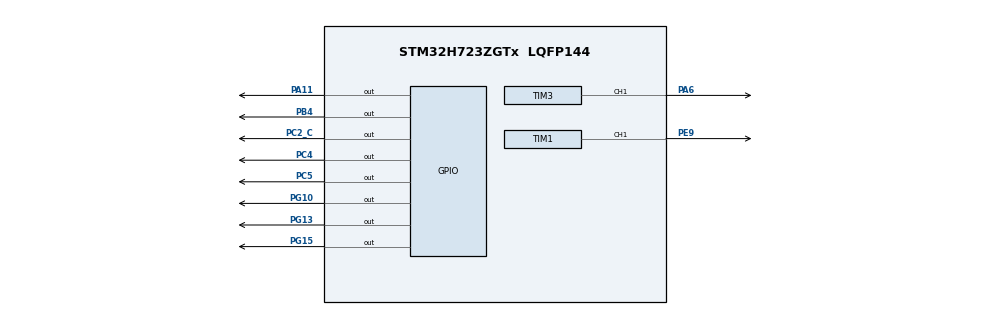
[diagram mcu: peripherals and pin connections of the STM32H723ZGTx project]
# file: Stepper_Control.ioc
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Mcu.Family=STM32H7
Mcu.Name=STM32H723ZGTx
Mcu.Package=LQFP144
NVIC.PriorityGroup=NVIC_PRIORITYGROUP_4
NVIC.TIM1_BRK_IRQn=true\:1\:0\:true\:false\:true\:true\:true\:true
NVIC.TIM23_IRQn=true\:0\:0\:false\:false\:true\:true\:true\:true
NVIC.TIM3_IRQn=true\:1\:0\:true\:false\:true\:true\:true\:true
PA11.Signal=GPIO_Output
PA13(JTMS/SWDIO).Mode=Serial_Wire
PA13(JTMS/SWDIO).Signal=DEBUG_JTMS-SWDIO
PA14(JTCK/SWCLK).Mode=Serial_Wire
PA14(JTCK/SWCLK).Signal=DEBUG_JTCK-SWCLK
PA6.Signal=S_TIM3_CH1
PB4(NJTRST).Signal=GPIO_Output
PC2_C.Signal=GPIO_Output
PC4.Signal=GPIO_Output
PC5.Signal=GPIO_Output
PE9.Signal=S_TIM1_CH1
PG10.PinState=GPIO_PIN_SET
PG10.Signal=GPIO_Output
PG13.PinState=GPIO_PIN_SET
PG13.Signal=GPIO_Output
PG15.Signal=GPIO_Output
PH0-OSC_IN.Mode=HSE-External-Oscillator
PH0-OSC_IN.Signal=RCC_OSC_IN
PH1-OSC_OUT.Mode=HSE-External-Oscillator
PH1-OSC_OUT.Signal=RCC_OSC_OUT
ProjectManager.HeapSize=0x200
ProjectManager.StackSize=0x400
ProjectManager.TargetToolchain=MDK-ARM V5.32
RCC.ADCFreq_Value=100000000
RCC.APB1Freq_Value=100000000
RCC.APB2Freq_Value=100000000
RCC.APB3Freq_Value=100000000
RCC.APB4Freq_Value=100000000
RCC.CortexFreq_Value=400000000
RCC.D1PPRE=RCC_APB3_DIV2
RCC.D2PPRE1=RCC_APB1_DIV2
RCC.D2PPRE2=RCC_APB2_DIV2
RCC.D3PPRE=RCC_APB4_DIV2
RCC.DIVM1=2
RCC.DIVM2=2
RCC.DIVN1=32
RCC.DIVN2=16
RCC.DIVP1=1
RCC.HCLKFreq_Value=200000000
RCC.HPRE=RCC_HCLK_DIV2
RCC.PLLFRACN=0
RCC.PLLSourceVirtual=RCC_PLLSOURCE_HSE
RCC.SYSCLKFreq_VALUE=400000000
RCC.SYSCLKSource=RCC_SYSCLKSOURCE_PLLCLK
RCC.USBFreq_Value=200000000
SH.S_TIM1_CH1.0=TIM1_CH1,PWM Generation1 CH1
SH.S_TIM3_CH1.0=TIM3_CH1,PWM Generation1 CH1
TIM1.AutoReloadPreload=TIM_AUTORELOAD_PRELOAD_ENABLE
TIM1.Channel-PWM\ Generation1\ CH1=TIM_CHANNEL_1
TIM1.Period=1000-1
TIM1.Prescaler=200-1
TIM1.Pulse-PWM\ Generation1\ CH1=500
TIM23.Period=1000-1
TIM23.Prescaler=200-1
TIM3.AutoReloadPreload=TIM_AUTORELOAD_PRELOAD_ENABLE
TIM3.Channel-PWM\ Generation1\ CH1=TIM_CHANNEL_1
TIM3.Period=1000-1
TIM3.Prescaler=200-1
TIM3.Pulse-PWM\ Generation1\ CH1=500
VP_TIM1_VS_ClockSourceINT.Mode=Internal
VP_TIM23_VS_ClockSourceINT.Mode=Internal
VP_TIM3_VS_ClockSourceINT.Mode=Internal
board=custom

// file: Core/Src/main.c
/* USER CODE BEGIN Header */
/**
  ******************************************************************************
  * @file           : main.c
  * @brief          : Main program body
  ******************************************************************************
  * @attention
  *
  * Copyright (c) 2025 STMicroelectronics.
  * All rights reserved.
  *
  * This software is licensed under terms that can be found in the LICENSE file
  * in the root directory of this software component.
  * If no LICENSE file comes with this software, it is provided AS-IS.
  *
  ******************************************************************************
  */
/* USER CODE END Header */
#include "main.h"
#include "tim.h"
#include "gpio.h"

/* USER CODE BEGIN Includes */
#include "Delay.h"

/* USER CODE END Includes */

void SystemClock_Config(void);

int main(void)
{

  /* MCU Configuration--------------------------------------------------------*/

  /* Reset of all peripherals, Initializes the Flash interface and the Systick. */
  HAL_Init();

  /* Configure the system clock */
  SystemClock_Config();

  /* Initialize all configured peripherals */
  MX_GPIO_Init();
  MX_TIM1_Init();
  MX_TIM3_Init();
  MX_TIM23_Init();
  /* USER CODE BEGIN 2 */
  DWT_Init();
  /* USER CODE END 2 */

  /* Infinite loop */
  /* USER CODE BEGIN WHILE */
  int16_t pluse_count = 0;

  while (1)
  {
    /* USER CODE END WHILE */

  }
}

void SystemClock_Config(void)
{
  RCC_OscInitTypeDef RCC_OscInitStruct = {0};
  RCC_ClkInitTypeDef RCC_ClkInitStruct = {0};

  /** Supply configuration update enable
  */
  HAL_PWREx_ConfigSupply(PWR_LDO_SUPPLY);

  /** Configure the main internal regulator output voltage
  */
  __HAL_PWR_VOLTAGESCALING_CONFIG(PWR_REGULATOR_VOLTAGE_SCALE1);

  while(!__HAL_PWR_GET_FLAG(PWR_FLAG_VOSRDY)) {}

  /** Initializes the RCC Oscillators according to the specified parameters
  * in the RCC_OscInitTypeDef structure.
  */
  RCC_OscInitStruct.OscillatorType = RCC_OSCILLATORTYPE_HSE;
  RCC_OscInitStruct.HSEState = RCC_HSE_ON;
  RCC_OscInitStruct.PLL.PLLState = RCC_PLL_ON;
  RCC_OscInitStruct.PLL.PLLSource = RCC_PLLSOURCE_HSE;
  RCC_OscInitStruct.PLL.PLLM = 2;
  RCC_OscInitStruct.PLL.PLLN = 32;
  RCC_OscInitStruct.PLL.PLLP = 1;
  RCC_OscInitStruct.PLL.PLLQ = 2;
  RCC_OscInitStruct.PLL.PLLR = 2;
  RCC_OscInitStruct.PLL.PLLRGE = RCC_PLL1VCIRANGE_3;
  RCC_OscInitStruct.PLL.PLLVCOSEL = RCC_PLL1VCOWIDE;
  RCC_OscInitStruct.PLL.PLLFRACN = 0;
  if (HAL_RCC_OscConfig(&RCC_OscInitStruct) != HAL_OK)
  {
    Error_Handler();
  }

  /** Initializes the CPU, AHB and APB buses clocks
  */
  RCC_ClkInitStruct.ClockType = RCC_CLOCKTYPE_HCLK|RCC_CLOCKTYPE_SYSCLK
                              |RCC_CLOCKTYPE_PCLK1|RCC_CLOCKTYPE_PCLK2
                              |RCC_CLOCKTYPE_D3PCLK1|RCC_CLOCKTYPE_D1PCLK1;
  RCC_ClkInitStruct.SYSCLKSource = RCC_SYSCLKSOURCE_PLLCLK;
  RCC_ClkInitStruct.SYSCLKDivider = RCC_SYSCLK_DIV1;
  RCC_ClkInitStruct.AHBCLKDivider = RCC_HCLK_DIV2;
  RCC_ClkInitStruct.APB3CLKDivider = RCC_APB3_DIV2;
  RCC_ClkInitStruct.APB1CLKDivider = RCC_APB1_DIV2;
  RCC_ClkInitStruct.APB2CLKDivider = RCC_APB2_DIV2;
  RCC_ClkInitStruct.APB4CLKDivider = RCC_APB4_DIV2;

  if (HAL_RCC_ClockConfig(&RCC_ClkInitStruct, FLASH_LATENCY_2) != HAL_OK)
  {
    Error_Handler();
  }
}

void Error_Handler(void)
{
  __disable_irq();
  while (1)
  {
  }
}
